# psoc4axx register map
Vendor: Cypress Semiconductor; Series: PSoC4Axx; File version: 1.0
CPU: CM0PLUS r0p1, little endian, no MPU, no FPU, VTOR, 2 interrupt priority bits
Registers are 32-bit, read-write, reset 0x0 unless marked. A register's access mark holds for its fields unless they carry their own. Offsets are from the block's base; [hi:lo] are bit positions; lines under a group give offsets from that group; {n}, {i} and the like mark numbered series.

## PASS0 — PASS top-level MMIO (PRB, DSABv2, BIST, DSI, INTR)
Base 0x403F0000
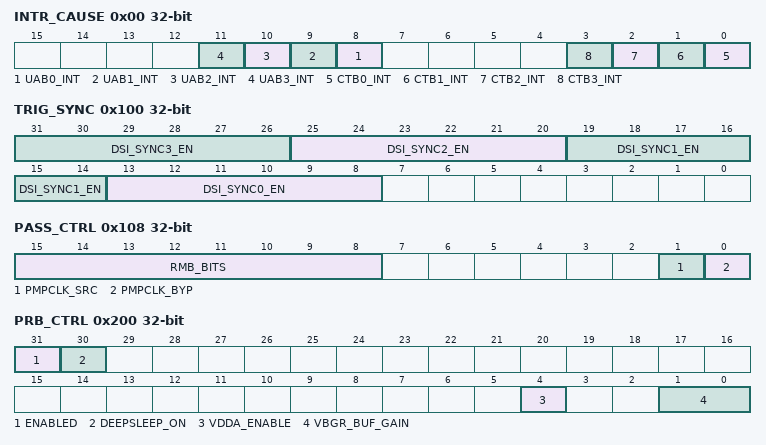
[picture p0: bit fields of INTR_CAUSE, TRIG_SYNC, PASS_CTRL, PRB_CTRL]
0x00 INTR_CAUSE ro — Interrupt cause register
  [n+8] UAB{n}_INT (n=0..3) — UAB{n} interrupt pending
  [n] CTB{n}_INT (n=0..3) — CTB{n} interrupt pending
0x100 TRIG_SYNC — Trigger synchronization bypass
  [6n+13:6n+8] DSI_SYNC{n}_EN (n=0..3) — Synchronize DSI input 1 (0: bypass synchronization)
0x104 SAR_TRIG_SEL reset 0x8000000 — Trigger select for SAR
  [28:24] TRIG_SEL — Trigger select 0=UAB0 half 0 trigger output 1=UAB0 half 1 trigger output 2=UAB1 half 0 trigger output 3=UAB1 half 1 trigger output 4=UAB2 half 0 trigger output 5=UAB2 half 1 trigger output 6=UAB3 half 0 trigger output 7=UAB3 half 1 trigger output 8-30 = generic trigger inputs 0-22 31=SAR trigger output For PASS4B only values 0-1 and 8-13 and 31 are legal.
0x108 PASS_CTRL — PASS control
  [15:8] RMB_BITS — Risk mitigation bits
  [1] PMPCLK_SRC — - 0: Pump clk is clk_hf - 1: Pump clk is direct from SRSS
  [0] PMPCLK_BYP — - 0: Pump clk is clk_hf/2 - 1: Pump clk is selected from PMPCLK_SRC
0x200 PRB_CTRL — global PRB control
  [31] ENABLED — - 0: PRB IP disabled (put analog in power down, open all switches) - 1: PRB IP enabled
  [30] DEEPSLEEP_ON — - 0: PRB IP disabled off during DeepSleep power mode - 1: PRB IP remains enabled during DeepSleep power mode (if ENABLED=1) Only VDDA reference is available in DeepSleep power mode
  [4] VDDA_ENABLE — - 0: VDDA references disabled (open switch at bottom of resistor ladder) - 1: VDDA references enabled (close switch at bottom of resistor ladder) This feature is available in DeepSleep power mode
  [1:0] VBGR_BUF_GAIN
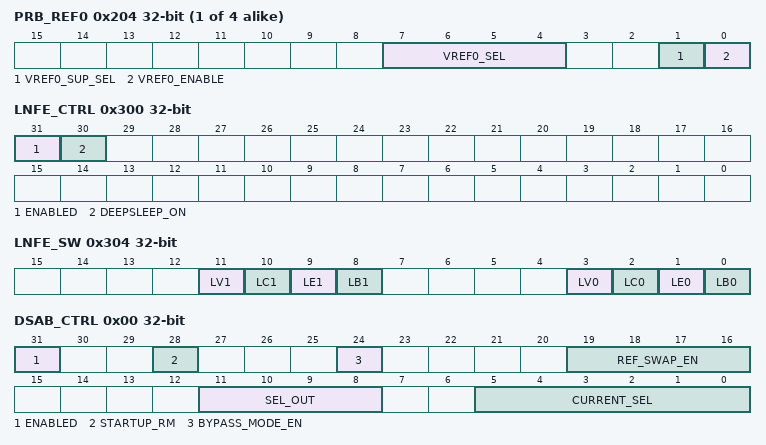
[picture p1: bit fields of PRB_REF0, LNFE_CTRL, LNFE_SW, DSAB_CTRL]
{0x204+4i} PRB_REF{i} (i=0..3) — VREF{i} control
  [7:4] VREF{i}_SEL — Level select, VTOP= VSUP * (VREF_SEL+1)/16 (15: VTOP=VSUP)
  [1] VREF{i}_SUP_SEL — Supply select 0: VSUP= VGBR * gain, 1: VSUP= VDDA
  [0] VREF{i}_ENABLE — 0=disconnect, 1= connect & enable resistor string
0x300 LNFE_CTRL — global LNFE control
  [31] ENABLED — - 0: LNFE IP disabled (put analog in power down, open all switches) - 1: LNFE IP enabled
  [30] DEEPSLEEP_ON — - 0: LNFE IP disabled off during DeepSleep power mode - 1: LNFE IP remains enabled during DeepSleep power mode (if ENABLED=1)
0x304 LNFE_SW — LNFE switch control
  [11] LV1 — Connect NPN1 Collector to Vdda
  [10] LC1 — Connect NPN1 Collector to pin P3
  [9] LE1 — Connect NPN1 Emitter to pin P5
  [8] LB1 — Connect NPN1 Base to pin P4
  [3] LV0 — Connect NPN0 Collector to Vdda
  [2] LC0 — Connect NPN0 Collector to pin P1
  [1] LE0 — Connect NPN0 Emitter to pin P6
  [0] LB0 — Connect NPN0 Base to pin P0
0xE00 DSAB group — DSAB configuration
  0x00 DSAB_CTRL — global DSAB control
    [31] ENABLED — This field (along with SEL_OUT and REF_SWAP_EN) provides bitwise selection of the current sources that drive the DSAB ZTC and PTAT outputs. See SEL_OUT field for truth tables. In SRSSLT devices, in active mode, this bit is overridden to '1', that is - it is always enabled in active mode.
    [28] STARTUP_RM — Risk mitigation control 1 - Force start the startup circuit
    [24] BYPASS_MODE_EN — 0 - DSAB PTAT generator is powered from DSAB regulator: VDDA must be at least 2.4V 1 - DSAB PTAT generator is pwoered directly from VDDA: VDDA cannot exceed 4.0V
    [19:16] REF_SWAP_EN — This field (along with SEL_OUT and ENABLED) provides bitwise selection of the current sources that drive the DSAB ZTC and PTAT outputs. See SEL_OUT field for truth tables.
    [11:8] SEL_OUT
    [5:0] CURRENT_SEL — DSAB DAC control field Nominal DSAB Output Current = CURRENT_SEL * 0.075 uA In products with SRSS-LITE, this setting impacts the CTB(m) offset. A value of 0x20 is used during factory trim and is required to maintain low offsets across temperature variation. If a different setting is used then a periodic re-trim of CTB(m) offset should be performed.
  0x04 DSAB_DFT — DFT bits
    [3:0] EN_DFT — - 0: DSAB DFT disabled - 1: DSAB DFT enabled (connect output to amuxbus) 0001 - PTAT<0> 0010 - PTAT<1> 0011 - PTAT<1:0> 0100 - PTAT<2> 0111 - PTAT<2:0> 1000 - PTAT<3> 1111 - PTAT<3:0> 1001 - DSAB Reg Out
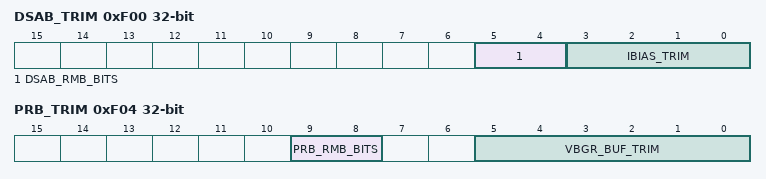
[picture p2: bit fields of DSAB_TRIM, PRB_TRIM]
0xF00 DSAB_TRIM — DSAB Trim bits
  [5:4] DSAB_RMB_BITS — Risk mitigation bits
  [3:0] IBIAS_TRIM — DSAB 1111=lowest, 0000=highest DSABv2 0000=lowest, 1111=highest
0xF04 PRB_TRIM — PRB Trim bits
  [9:8] PRB_RMB_BITS — Risk mitigation bits
  [5:0] VBGR_BUF_TRIM — 6 bits signed value [-32..31], ~1mV per step
